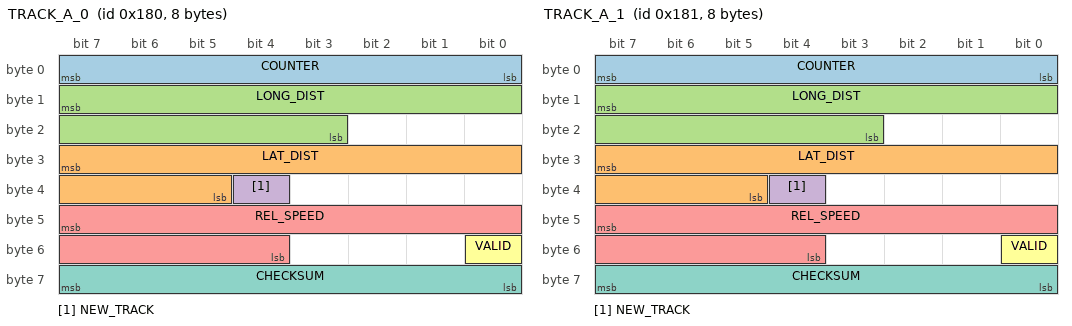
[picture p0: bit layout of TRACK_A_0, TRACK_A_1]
BO_ 384 TRACK_A_0: 8 XXX
 SG_ COUNTER : 7|8@0+ (1,0) [0|255] "" XXX
 SG_ LAT_DIST : 31|11@0- (0.04,0) [-50|50] "m" XXX
 SG_ LONG_DIST : 15|13@0+ (0.04,0) [0|300] "m" XXX
 SG_ NEW_TRACK : 36|1@0+ (1,0) [0|1] "" XXX
 SG_ REL_SPEED : 47|12@0- (0.025,0) [-100|100] "m/s" XXX
 SG_ VALID : 48|1@0+ (1,0) [0|1] "" XXX
 SG_ CHECKSUM : 63|8@0+ (1,0) [0|255] "" XXX

BO_ 385 TRACK_A_1: 8 XXX
 SG_ COUNTER : 7|8@0+ (1,0) [0|255] "" XXX
 SG_ LAT_DIST : 31|11@0- (0.04,0) [-50|50] "m" XXX
 SG_ LONG_DIST : 15|13@0+ (0.04,0) [0|300] "m" XXX
 SG_ NEW_TRACK : 36|1@0+ (1,0) [0|1] "" XXX
 SG_ REL_SPEED : 47|12@0- (0.025,0) [-100|100] "m/s" XXX
 SG_ VALID : 48|1@0+ (1,0) [0|1] "" XXX
 SG_ CHECKSUM : 63|8@0+ (1,0) [0|255] "" XXX

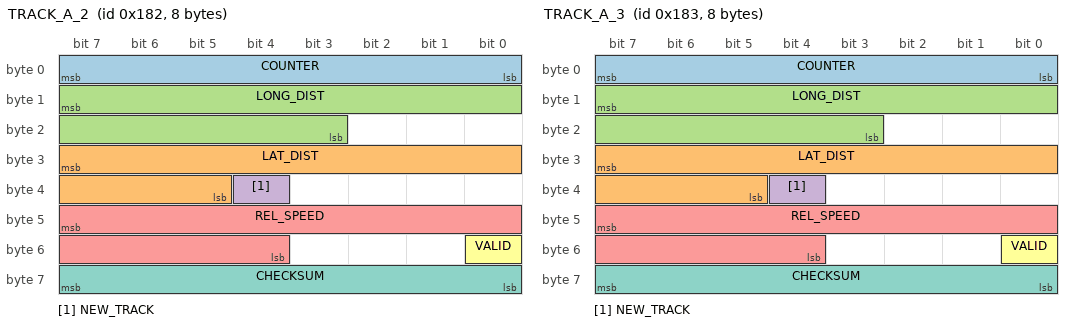
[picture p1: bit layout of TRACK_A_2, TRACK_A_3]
BO_ 386 TRACK_A_2: 8 XXX
 SG_ COUNTER : 7|8@0+ (1,0) [0|255] "" XXX
 SG_ LAT_DIST : 31|11@0- (0.04,0) [-50|50] "m" XXX
 SG_ LONG_DIST : 15|13@0+ (0.04,0) [0|300] "m" XXX
 SG_ NEW_TRACK : 36|1@0+ (1,0) [0|1] "" XXX
 SG_ REL_SPEED : 47|12@0- (0.025,0) [-100|100] "m/s" XXX
 SG_ VALID : 48|1@0+ (1,0) [0|1] "" XXX
 SG_ CHECKSUM : 63|8@0+ (1,0) [0|255] "" XXX

BO_ 387 TRACK_A_3: 8 XXX
 SG_ COUNTER : 7|8@0+ (1,0) [0|255] "" XXX
 SG_ LAT_DIST : 31|11@0- (0.04,0) [-50|50] "m" XXX
 SG_ LONG_DIST : 15|13@0+ (0.04,0) [0|300] "m" XXX
 SG_ NEW_TRACK : 36|1@0+ (1,0) [0|1] "" XXX
 SG_ REL_SPEED : 47|12@0- (0.025,0) [-100|100] "m/s" XXX
 SG_ VALID : 48|1@0+ (1,0) [0|1] "" XXX
 SG_ CHECKSUM : 63|8@0+ (1,0) [0|255] "" XXX

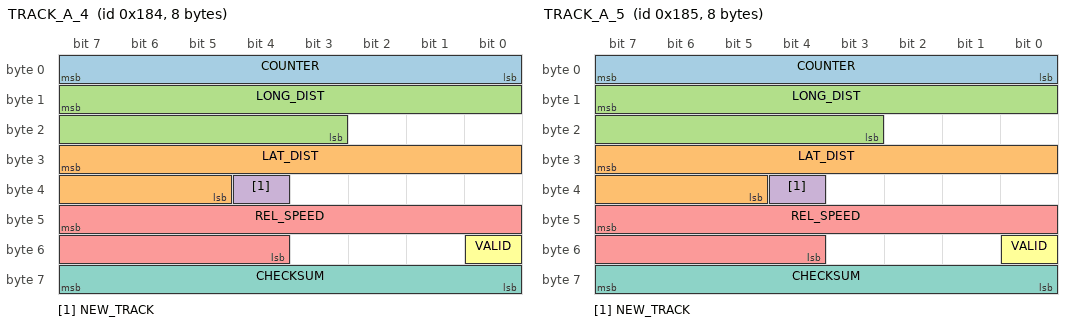
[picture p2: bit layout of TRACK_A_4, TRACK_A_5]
BO_ 388 TRACK_A_4: 8 XXX
 SG_ COUNTER : 7|8@0+ (1,0) [0|255] "" XXX
 SG_ LAT_DIST : 31|11@0- (0.04,0) [-50|50] "m" XXX
 SG_ LONG_DIST : 15|13@0+ (0.04,0) [0|300] "m" XXX
 SG_ NEW_TRACK : 36|1@0+ (1,0) [0|1] "" XXX
 SG_ REL_SPEED : 47|12@0- (0.025,0) [-100|100] "m/s" XXX
 SG_ VALID : 48|1@0+ (1,0) [0|1] "" XXX
 SG_ CHECKSUM : 63|8@0+ (1,0) [0|255] "" XXX

BO_ 389 TRACK_A_5: 8 XXX
 SG_ COUNTER : 7|8@0+ (1,0) [0|255] "" XXX
 SG_ LAT_DIST : 31|11@0- (0.04,0) [-50|50] "m" XXX
 SG_ LONG_DIST : 15|13@0+ (0.04,0) [0|300] "m" XXX
 SG_ NEW_TRACK : 36|1@0+ (1,0) [0|1] "" XXX
 SG_ REL_SPEED : 47|12@0- (0.025,0) [-100|100] "m/s" XXX
 SG_ VALID : 48|1@0+ (1,0) [0|1] "" XXX
 SG_ CHECKSUM : 63|8@0+ (1,0) [0|255] "" XXX

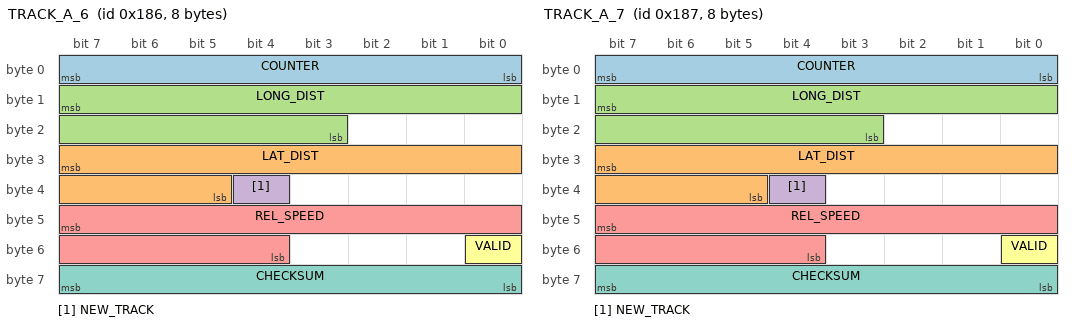
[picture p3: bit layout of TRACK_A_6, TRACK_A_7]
BO_ 390 TRACK_A_6: 8 XXX
 SG_ COUNTER : 7|8@0+ (1,0) [0|255] "" XXX
 SG_ LAT_DIST : 31|11@0- (0.04,0) [-50|50] "m" XXX
 SG_ LONG_DIST : 15|13@0+ (0.04,0) [0|300] "m" XXX
 SG_ NEW_TRACK : 36|1@0+ (1,0) [0|1] "" XXX
 SG_ REL_SPEED : 47|12@0- (0.025,0) [-100|100] "m/s" XXX
 SG_ VALID : 48|1@0+ (1,0) [0|1] "" XXX
 SG_ CHECKSUM : 63|8@0+ (1,0) [0|255] "" XXX

BO_ 391 TRACK_A_7: 8 XXX
 SG_ COUNTER : 7|8@0+ (1,0) [0|255] "" XXX
 SG_ LAT_DIST : 31|11@0- (0.04,0) [-50|50] "m" XXX
 SG_ LONG_DIST : 15|13@0+ (0.04,0) [0|300] "m" XXX
 SG_ NEW_TRACK : 36|1@0+ (1,0) [0|1] "" XXX
 SG_ REL_SPEED : 47|12@0- (0.025,0) [-100|100] "m/s" XXX
 SG_ VALID : 48|1@0+ (1,0) [0|1] "" XXX
 SG_ CHECKSUM : 63|8@0+ (1,0) [0|255] "" XXX

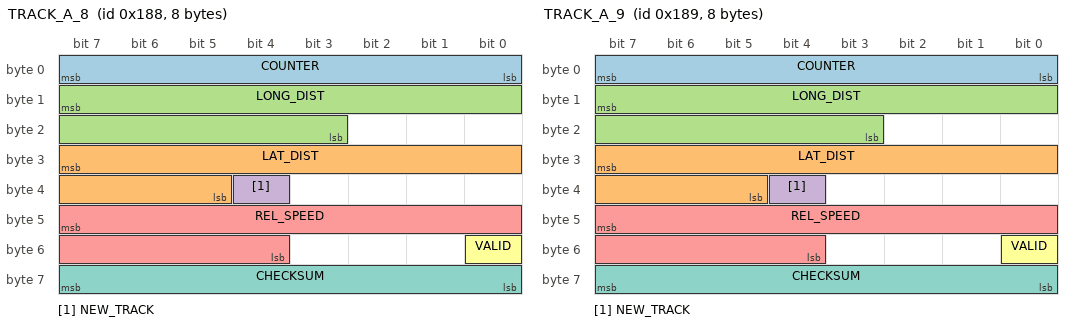
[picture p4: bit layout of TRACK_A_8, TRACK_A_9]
BO_ 392 TRACK_A_8: 8 XXX
 SG_ COUNTER : 7|8@0+ (1,0) [0|255] "" XXX
 SG_ LAT_DIST : 31|11@0- (0.04,0) [-50|50] "m" XXX
 SG_ LONG_DIST : 15|13@0+ (0.04,0) [0|300] "m" XXX
 SG_ NEW_TRACK : 36|1@0+ (1,0) [0|1] "" XXX
 SG_ REL_SPEED : 47|12@0- (0.025,0) [-100|100] "m/s" XXX
 SG_ VALID : 48|1@0+ (1,0) [0|1] "" XXX
 SG_ CHECKSUM : 63|8@0+ (1,0) [0|255] "" XXX

BO_ 393 TRACK_A_9: 8 XXX
 SG_ COUNTER : 7|8@0+ (1,0) [0|255] "" XXX
 SG_ LAT_DIST : 31|11@0- (0.04,0) [-50|50] "m" XXX
 SG_ LONG_DIST : 15|13@0+ (0.04,0) [0|300] "m" XXX
 SG_ NEW_TRACK : 36|1@0+ (1,0) [0|1] "" XXX
 SG_ REL_SPEED : 47|12@0- (0.025,0) [-100|100] "m/s" XXX
 SG_ VALID : 48|1@0+ (1,0) [0|1] "" XXX
 SG_ CHECKSUM : 63|8@0+ (1,0) [0|255] "" XXX

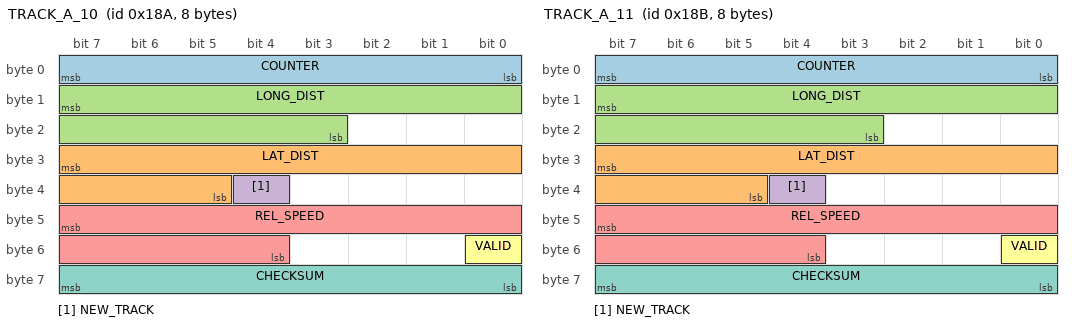
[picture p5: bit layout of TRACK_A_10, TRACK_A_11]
BO_ 394 TRACK_A_10: 8 XXX
 SG_ COUNTER : 7|8@0+ (1,0) [0|255] "" XXX
 SG_ LAT_DIST : 31|11@0- (0.04,0) [-50|50] "m" XXX
 SG_ LONG_DIST : 15|13@0+ (0.04,0) [0|300] "m" XXX
 SG_ NEW_TRACK : 36|1@0+ (1,0) [0|1] "" XXX
 SG_ REL_SPEED : 47|12@0- (0.025,0) [-100|100] "m/s" XXX
 SG_ VALID : 48|1@0+ (1,0) [0|1] "" XXX
 SG_ CHECKSUM : 63|8@0+ (1,0) [0|255] "" XXX

BO_ 395 TRACK_A_11: 8 XXX
 SG_ COUNTER : 7|8@0+ (1,0) [0|255] "" XXX
 SG_ LAT_DIST : 31|11@0- (0.04,0) [-50|50] "m" XXX
 SG_ LONG_DIST : 15|13@0+ (0.04,0) [0|300] "m" XXX
 SG_ NEW_TRACK : 36|1@0+ (1,0) [0|1] "" XXX
 SG_ REL_SPEED : 47|12@0- (0.025,0) [-100|100] "m/s" XXX
 SG_ VALID : 48|1@0+ (1,0) [0|1] "" XXX
 SG_ CHECKSUM : 63|8@0+ (1,0) [0|255] "" XXX

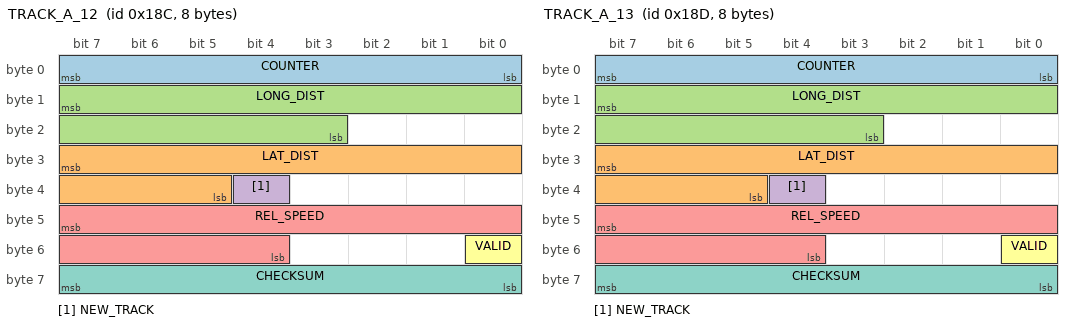
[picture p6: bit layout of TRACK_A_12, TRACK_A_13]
BO_ 396 TRACK_A_12: 8 XXX
 SG_ COUNTER : 7|8@0+ (1,0) [0|255] "" XXX
 SG_ LAT_DIST : 31|11@0- (0.04,0) [-50|50] "m" XXX
 SG_ LONG_DIST : 15|13@0+ (0.04,0) [0|300] "m" XXX
 SG_ NEW_TRACK : 36|1@0+ (1,0) [0|1] "" XXX
 SG_ REL_SPEED : 47|12@0- (0.025,0) [-100|100] "m/s" XXX
 SG_ VALID : 48|1@0+ (1,0) [0|1] "" XXX
 SG_ CHECKSUM : 63|8@0+ (1,0) [0|255] "" XXX

BO_ 397 TRACK_A_13: 8 XXX
 SG_ COUNTER : 7|8@0+ (1,0) [0|255] "" XXX
 SG_ LAT_DIST : 31|11@0- (0.04,0) [-50|50] "m" XXX
 SG_ LONG_DIST : 15|13@0+ (0.04,0) [0|300] "m" XXX
 SG_ NEW_TRACK : 36|1@0+ (1,0) [0|1] "" XXX
 SG_ REL_SPEED : 47|12@0- (0.025,0) [-100|100] "m/s" XXX
 SG_ VALID : 48|1@0+ (1,0) [0|1] "" XXX
 SG_ CHECKSUM : 63|8@0+ (1,0) [0|255] "" XXX

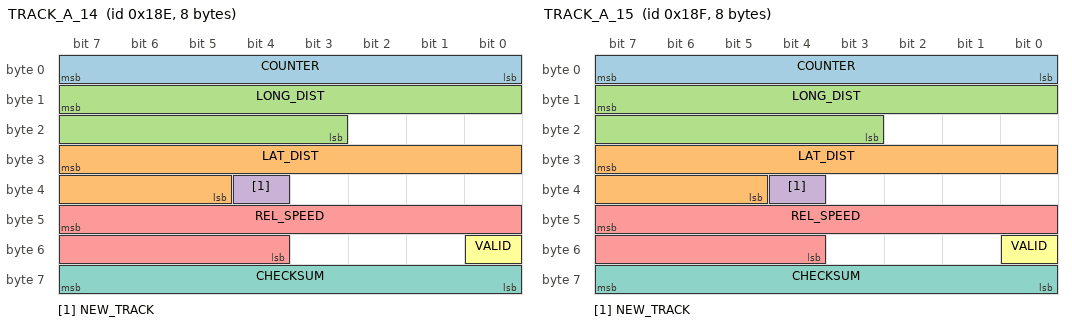
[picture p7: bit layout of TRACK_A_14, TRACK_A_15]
BO_ 398 TRACK_A_14: 8 XXX
 SG_ COUNTER : 7|8@0+ (1,0) [0|255] "" XXX
 SG_ LAT_DIST : 31|11@0- (0.04,0) [-50|50] "m" XXX
 SG_ LONG_DIST : 15|13@0+ (0.04,0) [0|300] "m" XXX
 SG_ NEW_TRACK : 36|1@0+ (1,0) [0|1] "" XXX
 SG_ REL_SPEED : 47|12@0- (0.025,0) [-100|100] "m/s" XXX
 SG_ VALID : 48|1@0+ (1,0) [0|1] "" XXX
 SG_ CHECKSUM : 63|8@0+ (1,0) [0|255] "" XXX

BO_ 399 TRACK_A_15: 8 XXX
 SG_ COUNTER : 7|8@0+ (1,0) [0|255] "" XXX
 SG_ LAT_DIST : 31|11@0- (0.04,0) [-50|50] "m" XXX
 SG_ LONG_DIST : 15|13@0+ (0.04,0) [0|300] "m" XXX
 SG_ NEW_TRACK : 36|1@0+ (1,0) [0|1] "" XXX
 SG_ REL_SPEED : 47|12@0- (0.025,0) [-100|100] "m/s" XXX
 SG_ VALID : 48|1@0+ (1,0) [0|1] "" XXX
 SG_ CHECKSUM : 63|8@0+ (1,0) [0|255] "" XXX

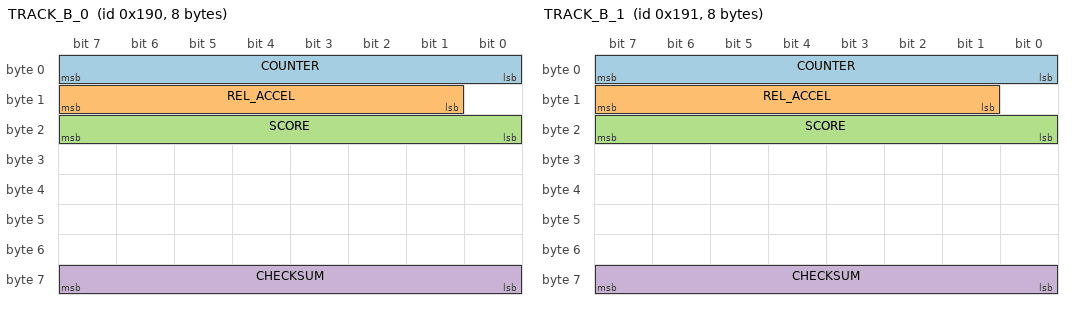
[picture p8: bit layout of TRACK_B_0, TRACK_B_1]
BO_ 400 TRACK_B_0: 8 XXX
 SG_ COUNTER : 7|8@0+ (1,0) [0|255] "" XXX
 SG_ REL_ACCEL : 15|7@0- (1,0) [-64|63] "" XXX
 SG_ SCORE : 23|8@0+ (1,0) [0|100] "" XXX
 SG_ CHECKSUM : 63|8@0+ (1,0) [0|255] "" XXX

BO_ 401 TRACK_B_1: 8 XXX
 SG_ COUNTER : 7|8@0+ (1,0) [0|255] "" XXX
 SG_ REL_ACCEL : 15|7@0- (1,0) [-64|63] "" XXX
 SG_ SCORE : 23|8@0+ (1,0) [0|100] "" XXX
 SG_ CHECKSUM : 63|8@0+ (1,0) [0|255] "" XXX

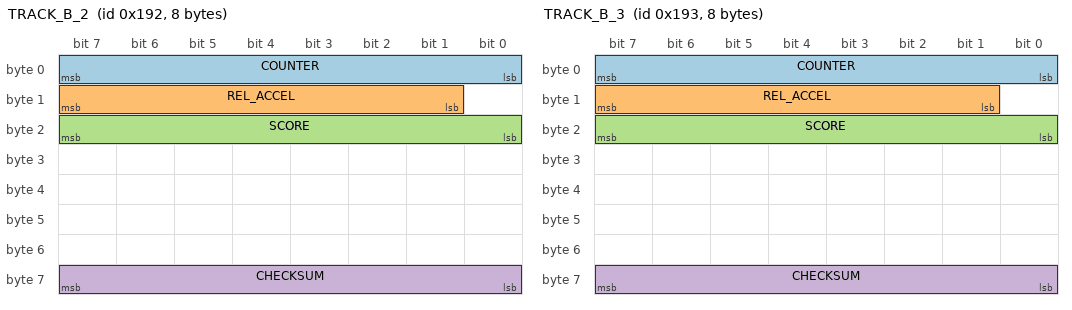
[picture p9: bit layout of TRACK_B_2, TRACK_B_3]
BO_ 402 TRACK_B_2: 8 XXX
 SG_ COUNTER : 7|8@0+ (1,0) [0|255] "" XXX
 SG_ REL_ACCEL : 15|7@0- (1,0) [-64|63] "" XXX
 SG_ SCORE : 23|8@0+ (1,0) [0|100] "" XXX
 SG_ CHECKSUM : 63|8@0+ (1,0) [0|255] "" XXX

BO_ 403 TRACK_B_3: 8 XXX
 SG_ COUNTER : 7|8@0+ (1,0) [0|255] "" XXX
 SG_ REL_ACCEL : 15|7@0- (1,0) [-64|63] "" XXX
 SG_ SCORE : 23|8@0+ (1,0) [0|100] "" XXX
 SG_ CHECKSUM : 63|8@0+ (1,0) [0|255] "" XXX

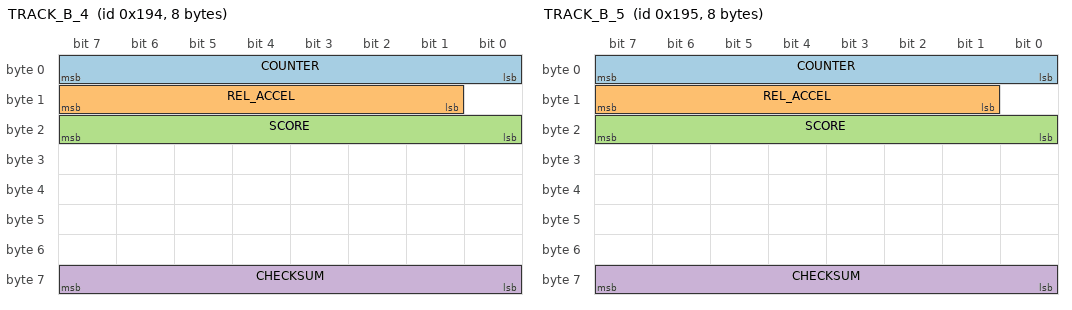
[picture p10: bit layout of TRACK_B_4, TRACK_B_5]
BO_ 404 TRACK_B_4: 8 XXX
 SG_ COUNTER : 7|8@0+ (1,0) [0|255] "" XXX
 SG_ REL_ACCEL : 15|7@0- (1,0) [-64|63] "" XXX
 SG_ SCORE : 23|8@0+ (1,0) [0|100] "" XXX
 SG_ CHECKSUM : 63|8@0+ (1,0) [0|255] "" XXX

BO_ 405 TRACK_B_5: 8 XXX
 SG_ COUNTER : 7|8@0+ (1,0) [0|255] "" XXX
 SG_ REL_ACCEL : 15|7@0- (1,0) [-64|63] "" XXX
 SG_ SCORE : 23|8@0+ (1,0) [0|100] "" XXX
 SG_ CHECKSUM : 63|8@0+ (1,0) [0|255] "" XXX

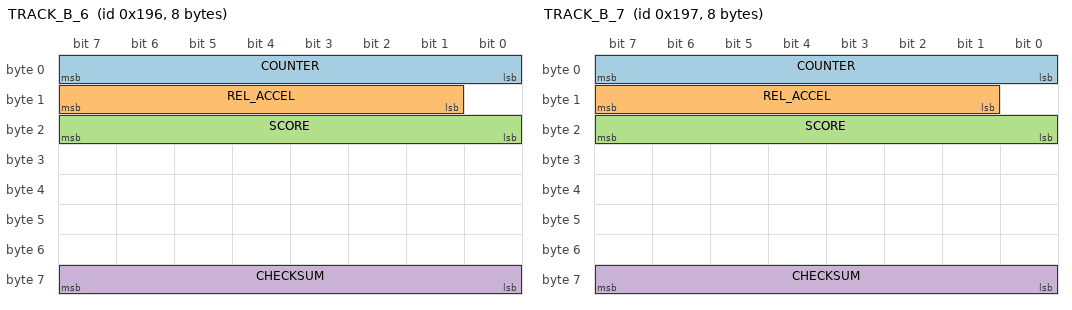
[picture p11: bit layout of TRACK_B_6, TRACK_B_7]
BO_ 406 TRACK_B_6: 8 XXX
 SG_ COUNTER : 7|8@0+ (1,0) [0|255] "" XXX
 SG_ REL_ACCEL : 15|7@0- (1,0) [-64|63] "" XXX
 SG_ SCORE : 23|8@0+ (1,0) [0|100] "" XXX
 SG_ CHECKSUM : 63|8@0+ (1,0) [0|255] "" XXX

BO_ 407 TRACK_B_7: 8 XXX
 SG_ COUNTER : 7|8@0+ (1,0) [0|255] "" XXX
 SG_ REL_ACCEL : 15|7@0- (1,0) [-64|63] "" XXX
 SG_ SCORE : 23|8@0+ (1,0) [0|100] "" XXX
 SG_ CHECKSUM : 63|8@0+ (1,0) [0|255] "" XXX

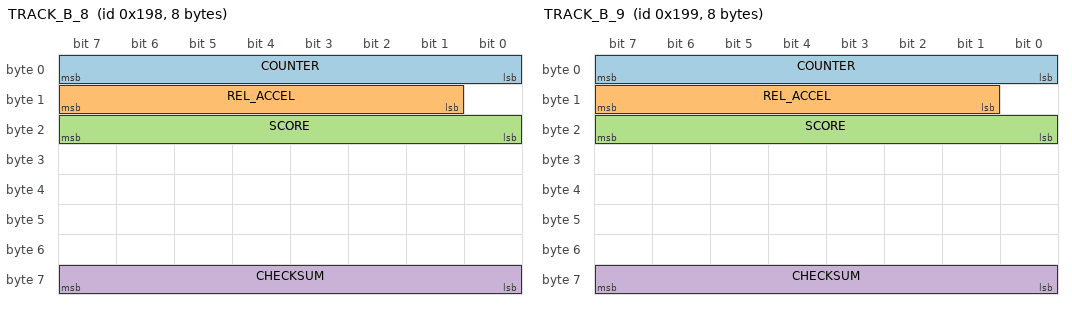
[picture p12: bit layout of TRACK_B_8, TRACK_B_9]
BO_ 408 TRACK_B_8: 8 XXX
 SG_ COUNTER : 7|8@0+ (1,0) [0|255] "" XXX
 SG_ REL_ACCEL : 15|7@0- (1,0) [-64|63] "" XXX
 SG_ SCORE : 23|8@0+ (1,0) [0|100] "" XXX
 SG_ CHECKSUM : 63|8@0+ (1,0) [0|255] "" XXX

BO_ 409 TRACK_B_9: 8 XXX
 SG_ COUNTER : 7|8@0+ (1,0) [0|255] "" XXX
 SG_ REL_ACCEL : 15|7@0- (1,0) [-64|63] "" XXX
 SG_ SCORE : 23|8@0+ (1,0) [0|100] "" XXX
 SG_ CHECKSUM : 63|8@0+ (1,0) [0|255] "" XXX

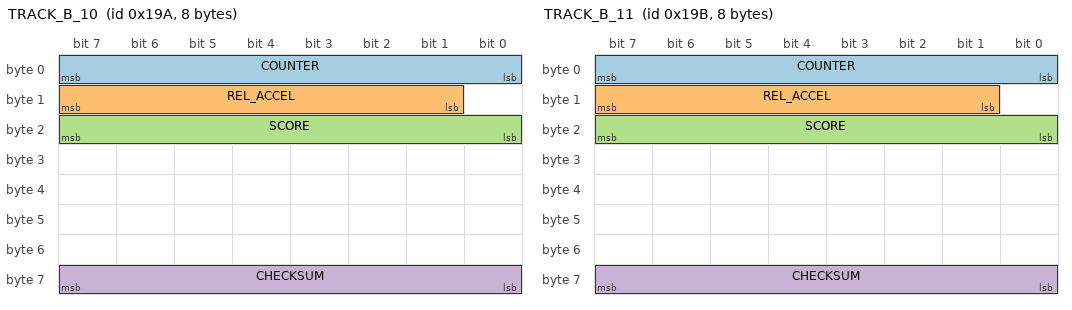
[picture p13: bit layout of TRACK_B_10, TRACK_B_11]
BO_ 410 TRACK_B_10: 8 XXX
 SG_ COUNTER : 7|8@0+ (1,0) [0|255] "" XXX
 SG_ REL_ACCEL : 15|7@0- (1,0) [-64|63] "" XXX
 SG_ SCORE : 23|8@0+ (1,0) [0|100] "" XXX
 SG_ CHECKSUM : 63|8@0+ (1,0) [0|255] "" XXX

BO_ 411 TRACK_B_11: 8 XXX
 SG_ COUNTER : 7|8@0+ (1,0) [0|255] "" XXX
 SG_ REL_ACCEL : 15|7@0- (1,0) [-64|63] "" XXX
 SG_ SCORE : 23|8@0+ (1,0) [0|100] "" XXX
 SG_ CHECKSUM : 63|8@0+ (1,0) [0|255] "" XXX

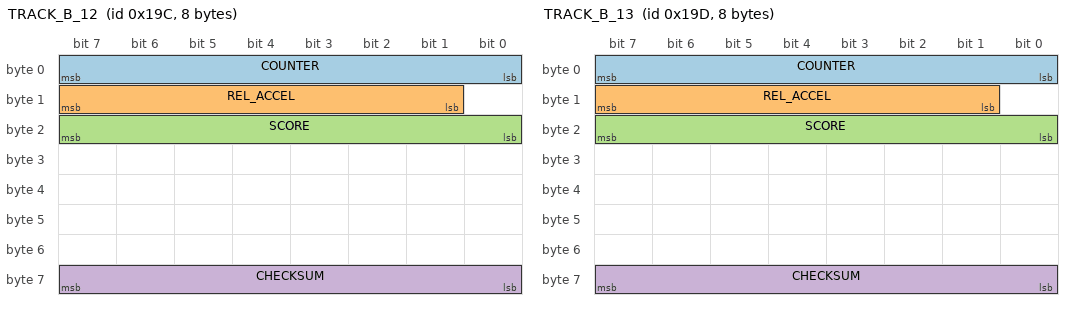
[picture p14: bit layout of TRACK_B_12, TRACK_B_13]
BO_ 412 TRACK_B_12: 8 XXX
 SG_ COUNTER : 7|8@0+ (1,0) [0|255] "" XXX
 SG_ REL_ACCEL : 15|7@0- (1,0) [-64|63] "" XXX
 SG_ SCORE : 23|8@0+ (1,0) [0|100] "" XXX
 SG_ CHECKSUM : 63|8@0+ (1,0) [0|255] "" XXX

BO_ 413 TRACK_B_13: 8 XXX
 SG_ COUNTER : 7|8@0+ (1,0) [0|255] "" XXX
 SG_ REL_ACCEL : 15|7@0- (1,0) [-64|63] "" XXX
 SG_ SCORE : 23|8@0+ (1,0) [0|100] "" XXX
 SG_ CHECKSUM : 63|8@0+ (1,0) [0|255] "" XXX

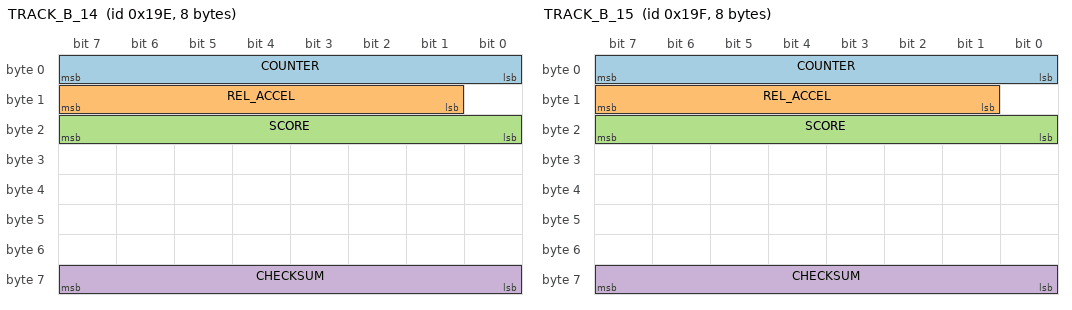
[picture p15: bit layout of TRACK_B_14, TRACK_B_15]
BO_ 414 TRACK_B_14: 8 XXX
 SG_ COUNTER : 7|8@0+ (1,0) [0|255] "" XXX
 SG_ REL_ACCEL : 15|7@0- (1,0) [-64|63] "" XXX
 SG_ SCORE : 23|8@0+ (1,0) [0|100] "" XXX
 SG_ CHECKSUM : 63|8@0+ (1,0) [0|255] "" XXX

BO_ 415 TRACK_B_15: 8 XXX
 SG_ COUNTER : 7|8@0+ (1,0) [0|255] "" XXX
 SG_ REL_ACCEL : 15|7@0- (1,0) [-64|63] "" XXX
 SG_ SCORE : 23|8@0+ (1,0) [0|100] "" XXX
 SG_ CHECKSUM : 63|8@0+ (1,0) [0|255] "" XXX

BO_ 576 NEW_MSG_1: 8 XXX
 SG_ NEW_SIGNAL_1 : 15|7@0+ (1,0) [0|127] "" XXX
 SG_ NEW_SIGNAL_2 : 23|8@0+ (1,0) [0|255] "" XXX

BU_: XXX

CM_ "AUTOGENERATED FILE, DO NOT EDIT";

CM_ "honda_crv_ex_2017_body.dbc starts here";
VAL_ 262 DI_torqueDriver -4096 "SNA" ;
VAL_ 262 DI_torqueMotor -4096 "SNA" ;
VAL_ 262 DI_soptState 7 "SOPT_TEST_SNA" 4 "SOPT_TEST_NOT_RUN" 3 "SOPT_TEST_PASSED" 2 "SOPT_TEST_FAILED" 1 "SOPT_TEST_IN_PROGRESS" 0 "SOPT_PRE_TEST" ;
VAL_ 262 DI_motorRPM -32768 "SNA" ;
VAL_ 262 DI_pedalPos 255 "SNA" ;
VAL_ 278 DI_torqueEstimate -2048 "SNA" ;
VAL_ 278 DI_gear 7 "DI_GEAR_SNA" 4 "DI_GEAR_D" 3 "DI_GEAR_N" 2 "DI_GEAR_R" 1 "DI_GEAR_P" 0 "DI_GEAR_INVALID" ;
VAL_ 278 DI_brakePedal 1 "Applied" 0 "Not_applied" ;
VAL_ 278 DI_vehicleSpeed 4095 "SNA" ;
VAL_ 278 DI_gearRequest 7 "DI_GEAR_SNA" 4 "DI_GEAR_D" 3 "DI_GEAR_N" 2 "DI_GEAR_R" 1 "DI_GEAR_P" 0 "DI_GEAR_INVALID" ;
VAL_ 278 DI_torqueInterfaceFailure 1 "TORQUE_INTERFACE_FAILED" 0 "TORQUE_INTERFACE_NORMAL" ;
VAL_ 278 DI_brakePedalState 3 "SNA" 2 "INVALID" 1 "ON" 0 "OFF" ;
VAL_ 278 DI_epbParkRequest 1 "Park_requested" 0 "No_request" ;
VAL_ 278 DI_epbInterfaceReady 1 "EPB_INTERFACE_READY" 0 "EPB_INTERFACE_NOT_READY" ;
VAL_ 504 driverBrakeStatus 2 "APPLIED" 1 "NOT_APPLIED" ;
VAL_ 568 SpdCtrlLvr_Stat 32 "DN_1ST" 16 "UP_1ST" 8 "DN_2ND" 4 "UP_2ND" 2 "RWD" 1 "FWD" 0 "IDLE" ;
VAL_ 568 DTR_Dist_Rq 255 "SNA" 200 "ACC_DIST_7" 166 "ACC_DIST_6" 133 "ACC_DIST_5" 100 "ACC_DIST_4" 66 "ACC_DIST_3" 33 "ACC_DIST_2" 0 "ACC_DIST_1" ;
VAL_ 568 TurnIndLvr_Stat 3 "SNA" 2 "RIGHT" 1 "LEFT" 0 "IDLE" ;
VAL_ 568 HiBmLvr_Stat 3 "SNA" 2 "HIBM_FLSH_ON_PSD" 1 "HIBM_ON_PSD" 0 "IDLE" ;
VAL_ 568 WprWashSw_Psd 3 "SNA" 2 "WASH" 1 "TIPWIPE" 0 "NPSD" ;
VAL_ 568 WprWash_R_Sw_Posn_V2 3 "SNA" 2 "WASH" 1 "INTERVAL" 0 "OFF" ;
VAL_ 568 StW_Lvr_Stat 4 "STW_BACK" 3 "STW_FWD" 2 "STW_DOWN" 1 "STW_UP" 0 "NPSD" ;
VAL_ 568 StW_Cond_Psd 3 "SNA" 2 "DOWN" 1 "UP" 0 "NPSD" ;
VAL_ 568 HrnSw_Psd 3 "SNA" 2 "NDEF2" 1 "PSD" 0 "NPSD" ;
VAL_ 568 StW_Sw00_Psd 1 "PRESSED" 0 "NOT_PRESSED_SNA" ;
VAL_ 568 StW_Sw01_Psd 1 "PRESSED" 0 "NOT_PRESSED_SNA" ;
VAL_ 568 StW_Sw03_Psd 1 "PRESSED" 0 "NOT_PRESSED_SNA" ;
VAL_ 568 StW_Sw04_Psd 1 "PRESSED" 0 "NOT_PRESSED_SNA" ;
VAL_ 568 WprSw6Posn 7 "SNA" 6 "STAGE2" 5 "STAGE1" 4 "INTERVAL4" 3 "INTERVAL3" 2 "INTERVAL2" 1 "INTERVAL1" 0 "OFF" ;
VAL_ 598 DI_aebState 2 "ENABLED" 4 "FAULT" 7 "SNA" 1 "STANDBY" 3 "STANDSTILL" 0 "UNAVAILABLE" ;
VAL_ 598 DI_analogSpeed 4095 "SNA" ;
VAL_ 598 DI_cruiseState 2 "ENABLED" 5 "FAULT" 0 "OFF" 4 "OVERRIDE" 7 "PRE_CANCEL" 6 "PRE_FAULT" 1 "STANDBY" 3 "STANDSTILL" ;
VAL_ 598 DI_digitalSpeed 255 "SNA" ;
VAL_ 598 DI_immobilizerState 2 "AUTHENTICATING" 3 "DISARMED" 6 "FAULT" 4 "IDLE" 0 "INIT_SNA" 1 "REQUEST" 5 "RESET" ;
VAL_ 598 DI_speedUnits 1 "KPH" 0 "MPH" ;
VAL_ 598 DI_state 3 "ABORT" 4 "ENABLE" 2 "FAULT" 1 "STANDBY" 0 "UNAVAILABLE" ;
VAL_ 598 DI_systemState 3 "ABORT" 4 "ENABLE" 2 "FAULT" 1 "STANDBY" 0 "UNAVAILABLE" ;
VAL_ 598 DI_vehicleHoldState 2 "BLEND_IN" 4 "BLEND_OUT" 6 "FAULT" 7 "INIT" 5 "PARK" 1 "STANDBY" 3 "STANDSTILL" 0 "UNAVAILABLE" ;
VAL_ 703 DAS_setSpeed 4095 "SNA" ;
VAL_ 703 DAS_accState 15 "FAULT_SNA" 13 "ACC_CANCEL_GENERIC_SILENT" 11 "APC_SELFPARK_START" 10 "APC_UNPARK_COMPLETE" 9 "APC_PAUSE" 8 "APC_ABORT" 7 "APC_COMPLETE" 6 "APC_FORWARD" 5 "APC_BACKWARD" 4 "ACC_ON" 3 "ACC_HOLD" 0 "ACC_CANCEL_GENERIC" ;
VAL_ 703 DAS_aebEvent 3 "AEB_SNA" 2 "AEB_FAULT" 1 "AEB_ACTIVE" 0 "AEB_NOT_ACTIVE" ;
VAL_ 703 DAS_jerkMin 511 "SNA" ;
VAL_ 703 DAS_jerkMax 255 "SNA" ;
VAL_ 703 DAS_accelMin 511 "SNA" ;
